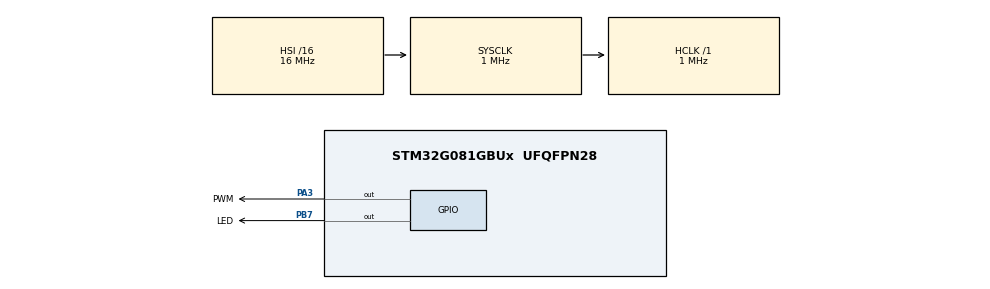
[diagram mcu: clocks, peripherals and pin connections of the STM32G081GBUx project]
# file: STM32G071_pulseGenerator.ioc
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Mcu.Family=STM32G0
Mcu.Name=STM32G081GBUx
Mcu.Package=UFQFPN28
PA13.Mode=Serial_Wire
PA13.Signal=SYS_SWDIO
PA14-BOOT0.Mode=Serial_Wire
PA14-BOOT0.Signal=SYS_SWCLK
PA3.GPIO_Label=PWM
PA3.Signal=GPIO_Output
PB7.GPIO_Label=LED
PB7.Signal=GPIO_Output
ProjectManager.HeapSize=0x200
ProjectManager.StackSize=0x400
ProjectManager.TargetToolchain=MDK-ARM V5.32
RCC.ADCFreq_Value=1000000
RCC.AHBFreq_Value=1000000
RCC.CortexFreq_Value=1000000
RCC.EXTERNAL_CLOCK_VALUE=48000
RCC.HCLKFreq_Value=1000000
RCC.HSE_VALUE=8000000
RCC.HSISYSCLKDivider=RCC_HSI_DIV16
RCC.HSI_VALUE=16000000
RCC.LSE_VALUE=32768
RCC.PLLM=RCC_PLLM_DIV2
RCC.PLLR=RCC_PLLR_DIV8
RCC.SYSCLKFreq_VALUE=1000000
RCC.VCOOutputFreq_Value=64000000
TIM17.Period=99
TIM17.Prescaler=0
VP_SYS_VS_DBSignals.Mode=DisableDeadBatterySignals
VP_TIM17_VS_ClockSourceINT.Mode=Enable_Timer
board=custom

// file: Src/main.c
/* USER CODE BEGIN Header */
/**
  ******************************************************************************
  * @file           : main.c
  * @brief          : Main program body
  ******************************************************************************
  * @attention
  *
  * <h2><center>&copy; Copyright (c) 2023 STMicroelectronics.
  * All rights reserved.</center></h2>
  *
  * This software component is licensed by ST under BSD 3-Clause license,
  * the "License"; You may not use this file except in compliance with the
  * License. You may obtain a copy of the License at:
  *                        opensource.org/licenses/BSD-3-Clause
  *
  ******************************************************************************
  */
/* USER CODE END Header */

#include "main.h"

TIM_HandleTypeDef htim17;

void SystemClock_Config(void);
static void MX_GPIO_Init(void);
static void MX_TIM17_Init(void);

int main(void)
{

  /* MCU Configuration--------------------------------------------------------*/

  /* Reset of all peripherals, Initializes the Flash interface and the Systick. */
  HAL_Init();

  /* Configure the system clock */
  SystemClock_Config();

  /* Initialize all configured peripherals */
  MX_GPIO_Init();
  MX_TIM17_Init();
  /* USER CODE BEGIN 2 */
	int pulse_width = 100;
	HAL_Delay(5000);
	HAL_GPIO_WritePin(LED_GPIO_Port,LED_Pin,1);
		for(int i=0;i<6;i++)
		{
			HAL_GPIO_WritePin(PWM_GPIO_Port,PWM_Pin,1);
			HAL_Delay(pulse_width);
			HAL_GPIO_WritePin(PWM_GPIO_Port,PWM_Pin,0);
			HAL_Delay(pulse_width);
		}
		HAL_GPIO_WritePin(LED_GPIO_Port,LED_Pin,0);

  /* USER CODE END 2 */

  /* Infinite loop */
  /* USER CODE BEGIN WHILE */
  while (1)
  {
		HAL_Delay(5000);
		HAL_GPIO_WritePin(LED_GPIO_Port,LED_Pin,1);
		for(int i=0;i<6;i++)
		{
			HAL_GPIO_WritePin(PWM_GPIO_Port,PWM_Pin,1);
			HAL_Delay(pulse_width);
			HAL_GPIO_WritePin(PWM_GPIO_Port,PWM_Pin,0);
			HAL_Delay(pulse_width);
		}
		HAL_GPIO_WritePin(LED_GPIO_Port,LED_Pin,0);
    /* USER CODE END WHILE */

  }
}

void SystemClock_Config(void)
{
  RCC_OscInitTypeDef RCC_OscInitStruct = {0};
  RCC_ClkInitTypeDef RCC_ClkInitStruct = {0};

  /** Configure the main internal regulator output voltage
  */
  HAL_PWREx_ControlVoltageScaling(PWR_REGULATOR_VOLTAGE_SCALE1);
  /** Initializes the CPU, AHB and APB busses clocks
  */
  RCC_OscInitStruct.OscillatorType = RCC_OSCILLATORTYPE_HSI;
  RCC_OscInitStruct.HSIState = RCC_HSI_ON;
  RCC_OscInitStruct.HSIDiv = RCC_HSI_DIV16;
  RCC_OscInitStruct.HSICalibrationValue = RCC_HSICALIBRATION_DEFAULT;
  RCC_OscInitStruct.PLL.PLLState = RCC_PLL_NONE;
  if (HAL_RCC_OscConfig(&RCC_OscInitStruct) != HAL_OK)
  {
    Error_Handler();
  }
  /** Initializes the CPU, AHB and APB busses clocks
  */
  RCC_ClkInitStruct.ClockType = RCC_CLOCKTYPE_HCLK|RCC_CLOCKTYPE_SYSCLK
                              |RCC_CLOCKTYPE_PCLK1;
  RCC_ClkInitStruct.SYSCLKSource = RCC_SYSCLKSOURCE_HSI;
  RCC_ClkInitStruct.AHBCLKDivider = RCC_SYSCLK_DIV1;
  RCC_ClkInitStruct.APB1CLKDivider = RCC_HCLK_DIV1;

  if (HAL_RCC_ClockConfig(&RCC_ClkInitStruct, FLASH_LATENCY_0) != HAL_OK)
  {
    Error_Handler();
  }
}

static void MX_TIM17_Init(void)
{

  htim17.Instance = TIM17;
  htim17.Init.Prescaler = 0;
  htim17.Init.CounterMode = TIM_COUNTERMODE_UP;
  htim17.Init.Period = 99;
  htim17.Init.ClockDivision = TIM_CLOCKDIVISION_DIV1;
  htim17.Init.RepetitionCounter = 0;
  htim17.Init.AutoReloadPreload = TIM_AUTORELOAD_PRELOAD_DISABLE;
  if (HAL_TIM_Base_Init(&htim17) != HAL_OK)
  {
    Error_Handler();
  }

}

static void MX_GPIO_Init(void)
{
  GPIO_InitTypeDef GPIO_InitStruct = {0};

  /* GPIO Ports Clock Enable */
  __HAL_RCC_GPIOA_CLK_ENABLE();
  __HAL_RCC_GPIOB_CLK_ENABLE();

  /*Configure GPIO pin Output Level */
  HAL_GPIO_WritePin(PWM_GPIO_Port, PWM_Pin, GPIO_PIN_RESET);

  /*Configure GPIO pin Output Level */
  HAL_GPIO_WritePin(LED_GPIO_Port, LED_Pin, GPIO_PIN_RESET);

  /*Configure GPIO pin : PWM_Pin */
  GPIO_InitStruct.Pin = PWM_Pin;
  GPIO_InitStruct.Mode = GPIO_MODE_OUTPUT_PP;
  GPIO_InitStruct.Pull = GPIO_NOPULL;
  GPIO_InitStruct.Speed = GPIO_SPEED_FREQ_LOW;
  HAL_GPIO_Init(PWM_GPIO_Port, &GPIO_InitStruct);

  /*Configure GPIO pin : LED_Pin */
  GPIO_InitStruct.Pin = LED_Pin;
  GPIO_InitStruct.Mode = GPIO_MODE_OUTPUT_PP;
  GPIO_InitStruct.Pull = GPIO_NOPULL;
  GPIO_InitStruct.Speed = GPIO_SPEED_FREQ_LOW;
  HAL_GPIO_Init(LED_GPIO_Port, &GPIO_InitStruct);

}

void Error_Handler(void)
{
}

/************************ (C) COPYRIGHT STMicroelectronics *****END OF FILE****/
